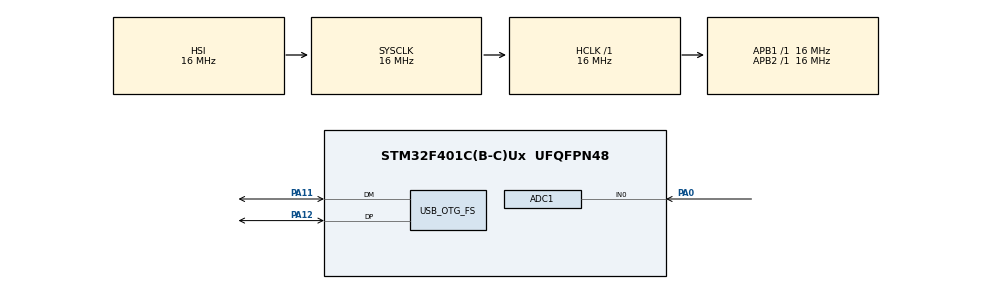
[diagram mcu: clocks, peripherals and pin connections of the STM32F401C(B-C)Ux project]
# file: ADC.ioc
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ADC1.Channel-4\#ChannelRegularConversion=ADC_CHANNEL_0
ADC1.ClockPrescaler=ADC_CLOCK_SYNC_PCLK_DIV8
ADC1.NbrOfConversionFlag=1
ADC1.Rank-4\#ChannelRegularConversion=1
ADC1.SamplingTime-4\#ChannelRegularConversion=ADC_SAMPLETIME_480CYCLES
ADC1.master=1
Mcu.Family=STM32F4
Mcu.Name=STM32F401C(B-C)Ux
Mcu.Package=UFQFPN48
NVIC.ADC_IRQn=true\:0\:0\:false\:false\:true\:true\:true
NVIC.OTG_FS_IRQn=true\:0\:0\:false\:false\:true\:false\:true
NVIC.PriorityGroup=NVIC_PRIORITYGROUP_4
PA0-WKUP.Signal=ADCx_IN0
PA11.Mode=Device_Only
PA11.Signal=USB_OTG_FS_DM
PA12.Mode=Device_Only
PA12.Signal=USB_OTG_FS_DP
PH0\ -\ OSC_IN.Mode=HSE-External-Oscillator
PH0\ -\ OSC_IN.Signal=RCC_OSC_IN
PH1\ -\ OSC_OUT.Mode=HSE-External-Oscillator
PH1\ -\ OSC_OUT.Signal=RCC_OSC_OUT
ProjectManager.HeapSize=0x200
ProjectManager.StackSize=0x400
ProjectManager.TargetToolchain=STM32CubeIDE
RCC.48MHZClocksFreq_Value=48000000
RCC.AHBFreq_Value=16000000
RCC.APB1Freq_Value=16000000
RCC.APB1TimFreq_Value=16000000
RCC.APB2Freq_Value=16000000
RCC.APB2TimFreq_Value=16000000
RCC.CortexFreq_Value=16000000
RCC.HCLKFreq_Value=16000000
RCC.HSE_VALUE=25000000
RCC.HSI_VALUE=16000000
RCC.LSE_VALUE=32768
RCC.PLLM=15
RCC.PLLN=144
RCC.PLLQ=5
RCC.SYSCLKFreq_VALUE=16000000
RCC.VCOOutputFreq_Value=240000000
SH.ADCx_IN0.0=ADC1_IN0,IN0
USB_DEVICE.CLASS_NAME_FS=CDC
USB_DEVICE.PRODUCT_STRING_CDC_FS=STM32 DAQBoard
USB_DEVICE.VirtualMode=Cdc
USB_DEVICE.VirtualModeFS=Cdc_FS
USB_OTG_FS.VirtualMode=Device_Only
VP_USB_DEVICE_VS_USB_DEVICE_CDC_FS.Mode=CDC_FS
board=custom

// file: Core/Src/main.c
/* USER CODE BEGIN Header */
/**
 ******************************************************************************
 * @file           : main.c
 * @brief          : Main program body
 ******************************************************************************
 * @attention
 *
 * <h2><center>&copy; Copyright (c) 2021 STMicroelectronics.
 * All rights reserved.</center></h2>
 *
 * This software component is licensed by ST under BSD 3-Clause license,
 * the "License"; You may not use this file except in compliance with the
 * License. You may obtain a copy of the License at:
 *                        opensource.org/licenses/BSD-3-Clause
 *
 ******************************************************************************
 */
/* USER CODE END Header */
#include "main.h"
#include "usb_device.h"

/* USER CODE BEGIN Includes */
#include "usbd_cdc_if.h" // Plik bedacy interfejsem uzytkownika do kontrolera USB
/* USER CODE END Includes */

ADC_HandleTypeDef hadc1;

/* USER CODE BEGIN PV */
uint16_t buffer[64];
/* USER CODE END PV */

void SystemClock_Config(void);
static void MX_GPIO_Init(void);
static void MX_ADC1_Init(void);

/* USER CODE BEGIN 0 */
void HAL_ADC_ConvCpltCallback(ADC_HandleTypeDef* hadc1){
//	buffer[0] = HAL_ADC_GetValue(hadc1);
	snprintf( buffer, sizeof(buffer), "%6d\n", HAL_ADC_GetValue(hadc1) );
//	CDC_Transmit_FS((uint8_t*)buffer, sizeof(uint16_t));
	CDC_Transmit_FS(buffer, 7);
	HAL_ADC_Start_IT(hadc1);
}
/* USER CODE END 0 */

int main(void)
{
  /* USER CODE BEGIN 1 */
//    // Calibrate The ADC On Power-Up For Better Accuracy
//    HAL_ADCEx_Calibration_Start(&hadc1);
  /* USER CODE END 1 */

  /* MCU Configuration--------------------------------------------------------*/

  /* Reset of all peripherals, Initializes the Flash interface and the Systick. */
  HAL_Init();

  /* Configure the system clock */
  SystemClock_Config();

  /* Initialize all configured peripherals */
  MX_GPIO_Init();
  MX_USB_DEVICE_Init();
  MX_ADC1_Init();
  /* USER CODE BEGIN 2 */
  HAL_ADC_Start_IT(&hadc1);

  /* USER CODE END 2 */

  /* Infinite loop */
	while (1) {

	}
}

void SystemClock_Config(void)
{
  RCC_OscInitTypeDef RCC_OscInitStruct = {0};
  RCC_ClkInitTypeDef RCC_ClkInitStruct = {0};

  /** Configure the main internal regulator output voltage
  */
  __HAL_RCC_PWR_CLK_ENABLE();
  __HAL_PWR_VOLTAGESCALING_CONFIG(PWR_REGULATOR_VOLTAGE_SCALE2);
  /** Initializes the RCC Oscillators according to the specified parameters
  * in the RCC_OscInitTypeDef structure.
  */
  RCC_OscInitStruct.OscillatorType = RCC_OSCILLATORTYPE_HSI|RCC_OSCILLATORTYPE_HSE;
  RCC_OscInitStruct.HSEState = RCC_HSE_ON;
  RCC_OscInitStruct.HSIState = RCC_HSI_ON;
  RCC_OscInitStruct.HSICalibrationValue = RCC_HSICALIBRATION_DEFAULT;
  RCC_OscInitStruct.PLL.PLLState = RCC_PLL_ON;
  RCC_OscInitStruct.PLL.PLLSource = RCC_PLLSOURCE_HSE;
  RCC_OscInitStruct.PLL.PLLM = 15;
  RCC_OscInitStruct.PLL.PLLN = 144;
  RCC_OscInitStruct.PLL.PLLP = RCC_PLLP_DIV2;
  RCC_OscInitStruct.PLL.PLLQ = 5;
  if (HAL_RCC_OscConfig(&RCC_OscInitStruct) != HAL_OK)
  {
    Error_Handler();
  }
  /** Initializes the CPU, AHB and APB buses clocks
  */
  RCC_ClkInitStruct.ClockType = RCC_CLOCKTYPE_HCLK|RCC_CLOCKTYPE_SYSCLK
                              |RCC_CLOCKTYPE_PCLK1|RCC_CLOCKTYPE_PCLK2;
  RCC_ClkInitStruct.SYSCLKSource = RCC_SYSCLKSOURCE_HSI;
  RCC_ClkInitStruct.AHBCLKDivider = RCC_SYSCLK_DIV1;
  RCC_ClkInitStruct.APB1CLKDivider = RCC_HCLK_DIV1;
  RCC_ClkInitStruct.APB2CLKDivider = RCC_HCLK_DIV1;

  if (HAL_RCC_ClockConfig(&RCC_ClkInitStruct, FLASH_LATENCY_0) != HAL_OK)
  {
    Error_Handler();
  }
}

static void MX_ADC1_Init(void)
{

  ADC_ChannelConfTypeDef sConfig = {0};

  /** Configure the global features of the ADC (Clock, Resolution, Data Alignment and number of conversion)
  */
  hadc1.Instance = ADC1;
  hadc1.Init.ClockPrescaler = ADC_CLOCK_SYNC_PCLK_DIV8;
  hadc1.Init.Resolution = ADC_RESOLUTION_12B;
  hadc1.Init.ScanConvMode = DISABLE;
  hadc1.Init.ContinuousConvMode = DISABLE;
  hadc1.Init.DiscontinuousConvMode = DISABLE;
  hadc1.Init.ExternalTrigConvEdge = ADC_EXTERNALTRIGCONVEDGE_NONE;
  hadc1.Init.ExternalTrigConv = ADC_SOFTWARE_START;
  hadc1.Init.DataAlign = ADC_DATAALIGN_RIGHT;
  hadc1.Init.NbrOfConversion = 1;
  hadc1.Init.DMAContinuousRequests = DISABLE;
  hadc1.Init.EOCSelection = ADC_EOC_SINGLE_CONV;
  if (HAL_ADC_Init(&hadc1) != HAL_OK)
  {
    Error_Handler();
  }
  /** Configure for the selected ADC regular channel its corresponding rank in the sequencer and its sample time.
  */
  sConfig.Channel = ADC_CHANNEL_0;
  sConfig.Rank = 1;
  sConfig.SamplingTime = ADC_SAMPLETIME_480CYCLES;
  if (HAL_ADC_ConfigChannel(&hadc1, &sConfig) != HAL_OK)
  {
    Error_Handler();
  }

}

static void MX_GPIO_Init(void)
{

  /* GPIO Ports Clock Enable */
  __HAL_RCC_GPIOH_CLK_ENABLE();
  __HAL_RCC_GPIOA_CLK_ENABLE();

}

void Error_Handler(void)
{
	__disable_irq();
	while (1) {
	}
}

/************************ (C) COPYRIGHT STMicroelectronics *****END OF FILE****/
